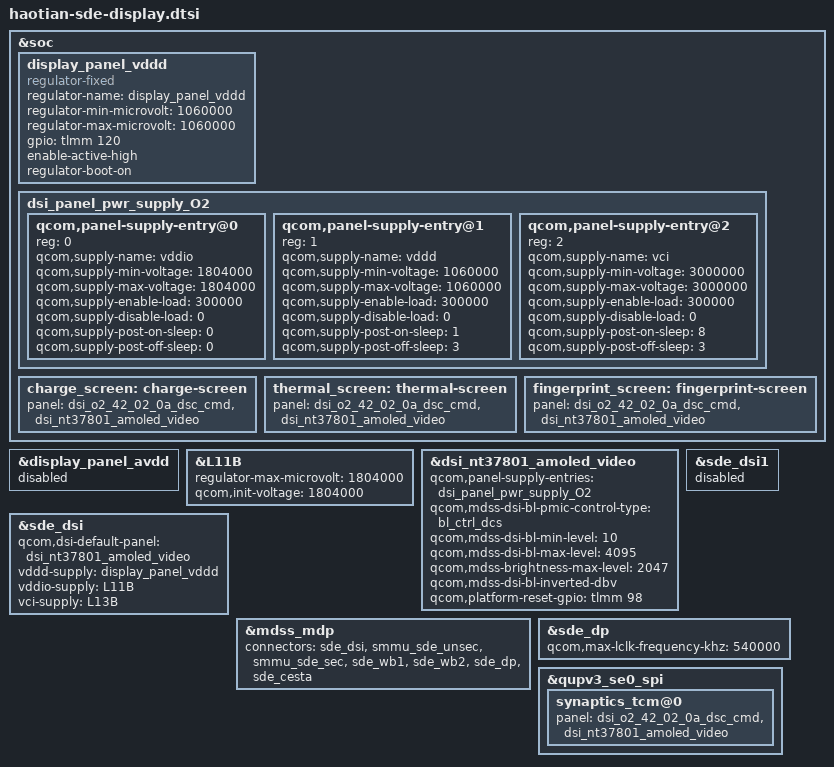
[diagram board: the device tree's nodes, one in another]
#include "sun-sde-display.dtsi"
#include "dsi-panel-o2-42-02-0a-dsc-cmd.dtsi"
#include "dsi-panel-nt37801-dsc-wqhd-plus-video.dtsi"


&soc {
    	display_panel_vddd: display_panel_vddd {
		compatible = "regulator-fixed";
		regulator-name = "display_panel_vddd";
		regulator-min-microvolt = <1060000>;
		regulator-max-microvolt = <1060000>;
		gpio = <&tlmm 120 0>;
		enable-active-high;
		regulator-boot-on;
    };

	dsi_panel_pwr_supply_O2: dsi_panel_pwr_supply_O2 {
		qcom,panel-supply-entry@0 {
			reg = <0>;
			qcom,supply-name = "vddio";
			qcom,supply-min-voltage = <1804000>;
			qcom,supply-max-voltage = <1804000>;
			qcom,supply-enable-load = <300000>;
			qcom,supply-disable-load = <0>;
			qcom,supply-post-on-sleep = <0>;
			qcom,supply-post-off-sleep = <0>;
		};
		qcom,panel-supply-entry@1 {
			reg = <1>;
			qcom,supply-name = "vddd";
			qcom,supply-min-voltage = <1060000>;
			qcom,supply-max-voltage = <1060000>;
			qcom,supply-enable-load = <300000>;
			qcom,supply-disable-load = <0>;
			qcom,supply-post-on-sleep = <1>;
			qcom,supply-post-off-sleep = <3>;
		};
		qcom,panel-supply-entry@2 {
			reg = <2>;
			qcom,supply-name = "vci";
			qcom,supply-min-voltage = <3000000>;
			qcom,supply-max-voltage = <3000000>;
			qcom,supply-enable-load = <300000>;
			qcom,supply-disable-load = <0>;
			qcom,supply-post-on-sleep = <8>;
			qcom,supply-post-off-sleep = <3>;
		};
	};
};

&display_panel_avdd {
	status = "disabled";
};

&L11B {
		regulator-max-microvolt = <1804000>;
		qcom,init-voltage = <1804000>;
};

&dsi_nt37801_amoled_video {
	qcom,panel-supply-entries = <&dsi_panel_pwr_supply_O2>;
	qcom,mdss-dsi-bl-pmic-control-type = "bl_ctrl_dcs";
	qcom,mdss-dsi-bl-min-level = <10>;
	qcom,mdss-dsi-bl-max-level = <4095>;
	qcom,mdss-brightness-max-level = <2047>;
	qcom,mdss-dsi-bl-inverted-dbv;
	qcom,platform-reset-gpio = <&tlmm 98 0>;
};

&sde_dsi {
	qcom,dsi-default-panel = <&dsi_nt37801_amoled_video>;
	vddd-supply = <&display_panel_vddd>;
	vddio-supply = <&L11B>;
	vci-supply = <&L13B>;
};

&sde_dsi1 {
	status = "disabled";
};

&mdss_mdp {
	connectors = <&sde_dsi &smmu_sde_unsec &smmu_sde_sec &sde_wb1 &sde_wb2 &sde_dp &sde_cesta>;
};

&sde_dp {
	qcom,max-lclk-frequency-khz = <540000>;
	status = "ok";
};

&qupv3_se0_spi {
	synaptics_tcm@0 {
		panel = <&dsi_o2_42_02_0a_dsc_cmd
			&dsi_nt37801_amoled_video>;
	};
};

&soc {
	charge_screen: charge-screen {
		panel  = <&dsi_o2_42_02_0a_dsc_cmd
			&dsi_nt37801_amoled_video>;
	};
};

&soc {
	thermal_screen: thermal-screen {
		panel = <&dsi_o2_42_02_0a_dsc_cmd
			&dsi_nt37801_amoled_video>;
	};
	fingerprint_screen: fingerprint-screen {
		panel = <&dsi_o2_42_02_0a_dsc_cmd
			&dsi_nt37801_amoled_video>;
	};
};
